# qei register map
Vendor: Texas Instruments
Peripheral module from a debugger description file (folder sc4ce93xh6pm).
Registers are 32-bit, read-write, no defined reset value unless marked. A register's access mark holds for its fields unless they carry their own. Offsets are as the file gives them; lines under a group give offsets from that group; [hi:lo] are bit positions; {n}, {i} and the like mark numbered series; 'fields as' and 'values as' point back to an identical list; <NAME> marks a mode.

## QEI0 — QEI register offsets
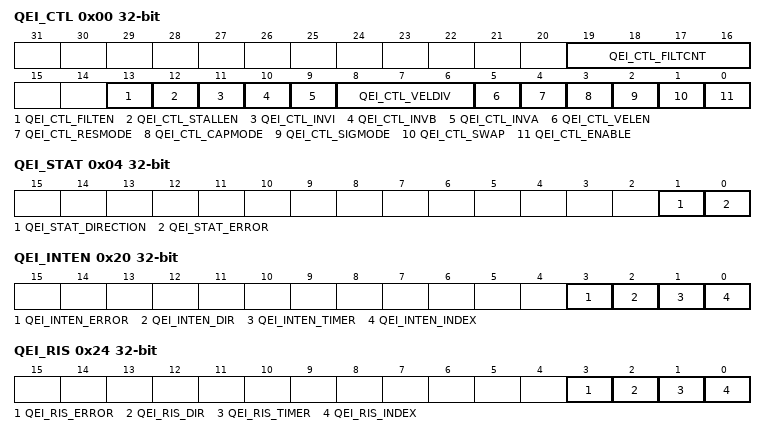
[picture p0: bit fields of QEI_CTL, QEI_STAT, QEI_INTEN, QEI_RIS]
0x00 QEI_CTL — QEI Control
  [19:16] QEI_CTL_FILTCNT — Input Filter Prescale Count
  [13] QEI_CTL_FILTEN — Enable Input Filter
  [12] QEI_CTL_STALLEN — Stall QEI
  [11] QEI_CTL_INVI — Invert Index Pulse
  [10] QEI_CTL_INVB — Invert PhB
  [9] QEI_CTL_INVA — Invert PhA
  [8:6] QEI_CTL_VELDIV — Predivide Velocity
    0=QEI clock /1; 1=QEI clock /2; 2=QEI clock /4; 3=QEI clock /8; 4=QEI clock /16; 5=QEI clock /32; 6=QEI clock /64; 7=QEI clock /128
  [5] QEI_CTL_VELEN — Capture Velocity
  [4] QEI_CTL_RESMODE — Reset Mode
  [3] QEI_CTL_CAPMODE — Capture Mode
  [2] QEI_CTL_SIGMODE — Signal Mode
  [1] QEI_CTL_SWAP — Swap Signals
  [0] QEI_CTL_ENABLE — Enable QEI
0x04 QEI_STAT ro — QEI Status
  [1] QEI_STAT_DIRECTION — Direction of Rotation
  [0] QEI_STAT_ERROR — Error Detected
0x08 QEI_POS — QEI Position
  [31:0] QEI_POS — Current Position Integrator Value
0x0C QEI_MAXPOS — QEI Maximum Position
  [31:0] QEI_MAXPOS — Maximum Position Integrator Value
0x10 QEI_LOAD — QEI Timer Load
  [31:0] QEI_LOAD — Velocity Timer Load Value
0x14 QEI_TIME ro — QEI Timer
  [31:0] QEI_TIME — Velocity Timer Current Value
0x18 QEI_COUNT ro — QEI Velocity Counter
  [31:0] QEI_COUNT — Velocity Pulse Count
0x1C QEI_SPEED ro — QEI Velocity
  [31:0] QEI_SPEED — Velocity
0x20 QEI_INTEN — QEI Interrupt Enable
  [3] QEI_INTEN_ERROR — Phase Error Interrupt Enable
  [2] QEI_INTEN_DIR — Direction Change Interrupt Enable
  [1] QEI_INTEN_TIMER — Timer Expires Interrupt Enable
  [0] QEI_INTEN_INDEX — Index Pulse Detected Interrupt Enable
0x24 QEI_RIS ro — QEI Raw Interrupt Status
  [3] QEI_RIS_ERROR — Phase Error Detected
  [2] QEI_RIS_DIR — Direction Change Detected
  [1] QEI_RIS_TIMER — Velocity Timer Expired
  [0] QEI_RIS_INDEX — Index Pulse Asserted
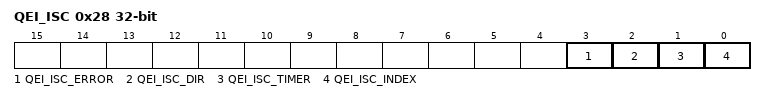
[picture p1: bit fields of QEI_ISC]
0x28 QEI_ISC — QEI Interrupt Status and Clear
  [3] QEI_ISC_ERROR — Phase Error Interrupt
  [2] QEI_ISC_DIR — Direction Change Interrupt
  [1] QEI_ISC_TIMER — Velocity Timer Expired Interrupt
  [0] QEI_ISC_INDEX — Index Pulse Interrupt
